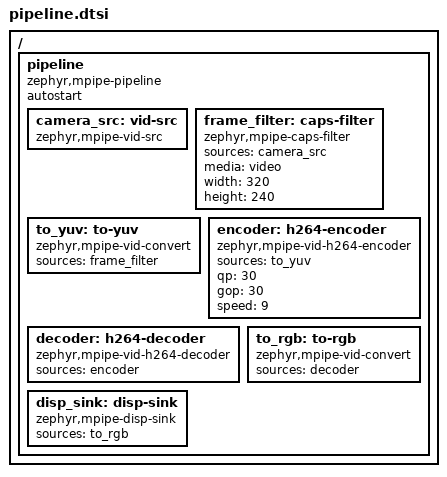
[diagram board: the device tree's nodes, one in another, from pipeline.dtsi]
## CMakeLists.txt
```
# Copyright 2026 NXP
# SPDX-License-Identifier: Apache-2.0

cmake_minimum_required(VERSION 3.20.0)
find_package(Zephyr REQUIRED HINTS $ENV{ZEPHYR_BASE})
project(mpipe_h264_enc_dec)

target_sources(app PRIVATE src/main.c)

if(CONFIG_CODEC_CODE_RELOCATE)
  # The code every frame goes through: the two codec libraries and the pixel
  # format conversions.
  zephyr_code_relocate(LIBRARY modules__minih264
    LOCATION "${CONFIG_CODEC_CODE_RAM_NAME}_TEXT" NOKEEP)
  zephyr_code_relocate(LIBRARY modules__h264swdec
    LOCATION "${CONFIG_CODEC_CODE_RAM_NAME}_TEXT" NOKEEP)
  zephyr_code_relocate(FILES ${ZEPHYR_BASE}/subsys/mpipe/vid/mpipe_vid_convert_table.c
    LOCATION "${CONFIG_CODEC_CODE_RAM_NAME}_TEXT" NOKEEP)
endif()

if(CONFIG_CODEC_DATA_RELOCATE)
  # The memory the codecs work in: the state and working area of the encoder,
  # the heap of the decoder.
  zephyr_code_relocate(FILES ${ZEPHYR_BASE}/subsys/mpipe/vid/mpipe_vid_h264_encoder.c
    LOCATION "${CONFIG_CODEC_ENCODER_RAM_NAME}_BSS" NOKEEP)
  zephyr_code_relocate(FILES ${ZEPHYR_BASE}/modules/h264swdec/zephyr_h264swdec.c
    LOCATION "${CONFIG_CODEC_DECODER_RAM_NAME}_NOINIT" NOKEEP)
endif()
```

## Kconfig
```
# Copyright 2026 NXP
# SPDX-License-Identifier: Apache-2.0

mainmenu "H.264 encode and decode pipeline sample"

menu "H.264 encode and decode pipeline configuration"

config CODEC_CODE_RELOCATE
	bool "Relocate the codec code into RAM"
	select CODE_DATA_RELOCATION
	help
	  Run the encoder, the decoder and the pixel format conversions from
	  RAM instead of the flash. On a microcontroller that executes in
	  place from a serial flash this is where most of their time goes.

if CODEC_CODE_RELOCATE

config CODEC_CODE_RAM_NAME
	string "Codec code RAM location"
	default "RAM"
	help
	  Memory region the codec code is relocated to.

endif # CODEC_CODE_RELOCATE

config CODEC_DATA_RELOCATE
	bool "Relocate the codec memory"
	select CODE_DATA_RELOCATION
	help
	  Place the state and working area of the encoder and the heap of the
	  decoder in named memory regions, on a board whose default RAM is
	  slower than another one it has.

if CODEC_DATA_RELOCATE

config CODEC_ENCODER_RAM_NAME
	string "Encoder memory location"
	default "RAM"
	help
	  Memory region holding the state and working area of the encoder.

config CODEC_DECODER_RAM_NAME
	string "Decoder memory location"
	default "RAM"
	help
	  Memory region holding the heap of the decoder.

endif # CODEC_DATA_RELOCATE

endmenu

source "Kconfig.zephyr"
```

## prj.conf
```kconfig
CONFIG_LOG=y

# The framework, its elements and the player are enabled by the pipeline node
CONFIG_MPIPE_STRUCTURE_MAX_FIELDS=4
# Buffer headers in flight: the camera frame, the two converted frames, the
# frame on screen, slack
CONFIG_MPIPE_NET_BUF_POOL_COUNT=6

# Video buffers of every pool in the image: the camera's own queue of 320x240
# BGRX32 frames, the frames of the two converters, slack
CONFIG_VIDEO_BUFFER_POOL_NUM_MAX=10
CONFIG_VIDEO_BUFFER_POOL_HEAP_SIZE=2097152

# Picture buffers of the decoder for a 320x240 stream
CONFIG_H264SWDEC_HEAP_SIZE=393216
CONFIG_H264SWDEC_MAX_FRAME_WIDTH=320
CONFIG_H264SWDEC_MAX_FRAME_HEIGHT=240
CONFIG_H264SWDEC_MAX_FRAME_SIZE=76800

# The bus carries end-of-stream and errors, never data: it needs neither
# zbus priority boost nor zbus logging of its own.
CONFIG_ZBUS_PRIORITY_BOOST=n
CONFIG_ZBUS_LOG_LEVEL_ERR=y
```

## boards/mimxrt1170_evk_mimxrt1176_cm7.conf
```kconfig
# The decoded frames are scanned out from a display plane: no driver framebuffer
CONFIG_MCUX_LCDIFV2_FB_NUM=0

# The encoder and the decoder run in the streaming thread
CONFIG_MPIPE_THREAD_STACK_SIZE=32768

# The flash is a serial one: the codecs run from the instruction TCM
CONFIG_CODEC_CODE_RELOCATE=y
CONFIG_CODEC_CODE_RAM_NAME="ITCM"

# The default RAM is the SDRAM: the codecs work in the on-chip RAM
CONFIG_CODEC_DATA_RELOCATE=y
CONFIG_CODEC_ENCODER_RAM_NAME="OCRAM1"
CONFIG_CODEC_DECODER_RAM_NAME="OCRAM2"

# Code that runs from RAM gains from being optimized for speed
CONFIG_SPEED_OPTIMIZATIONS=y
```

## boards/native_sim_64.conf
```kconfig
# Bind the native PTY UART to stdin/stdout so the shell reads keystrokes typed
# on the launching terminal.
CONFIG_UART_NATIVE_PTY_0_ON_STDINOUT=y

# Log directly to stdout via the native backend, which is active from boot,
# and not a second time through the shell.
CONFIG_LOG_BACKEND_NATIVE_POSIX=y
CONFIG_SHELL_LOG_BACKEND=n

# Threads on native_sim run on host stacks, so this size is never used and
# only reserves memory.
CONFIG_MPIPE_PLAYER_WORKER_STACK_SIZE=64
```

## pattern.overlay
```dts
/*
 * Copyright 2026 NXP
 *
 * SPDX-License-Identifier: Apache-2.0
 */

/*
 * A pattern that moves, drawn over the camera frames before they are encoded:
 * the codecs then have the same work on every board and in every light.
 */
&{/pipeline} {
	pattern: pattern {
		compatible = "zephyr,mpipe-vid-overlay";
		sources = <&frame_filter>;
		mode = "in-place";
		draw-callback = "sample_draw_pattern";
	};
};

&to_yuv {
	sources = <&pattern>;
};
```

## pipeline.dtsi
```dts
/*
 * Copyright 2026 NXP
 *
 * SPDX-License-Identifier: Apache-2.0
 */

/*
 * Camera frames encoded to H.264, decoded again and displayed: what the
 * display shows is what a receiver of the stream would see.
 *
 *   vid_src -> caps_filter -> vid_convert -> vid_h264_encoder
 *           -> vid_h264_decoder -> vid_convert -> disp_sink
 */
/ {
	pipeline {
		compatible = "zephyr,mpipe-pipeline";
		autostart;

		camera_src: vid-src {
			compatible = "zephyr,mpipe-vid-src";
		};

		/* The frame size the memory of the encoder is reserved for */
		frame_filter: caps-filter {
			compatible = "zephyr,mpipe-caps-filter";
			sources = <&camera_src>;
			media = "video";
			width = <320>;
			height = <240>;
		};

		to_yuv: to-yuv {
			compatible = "zephyr,mpipe-vid-convert";
			sources = <&frame_filter>;
		};

		/* Speed 9 is the fastest setting that keeps the deblocking filter */
		encoder: h264-encoder {
			compatible = "zephyr,mpipe-vid-h264-encoder";
			sources = <&to_yuv>;
			qp = <30>;
			gop = <30>;
			speed = <9>;
		};

		decoder: h264-decoder {
			compatible = "zephyr,mpipe-vid-h264-decoder";
			sources = <&encoder>;
		};

		to_rgb: to-rgb {
			compatible = "zephyr,mpipe-vid-convert";
			sources = <&decoder>;
		};

		disp_sink: disp-sink {
			compatible = "zephyr,mpipe-disp-sink";
			sources = <&to_rgb>;
		};
	};
};
```

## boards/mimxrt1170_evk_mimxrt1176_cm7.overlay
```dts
/*
 * Copyright 2026 NXP
 *
 * SPDX-License-Identifier: Apache-2.0
 */

#include "../pipeline.dtsi"

/* The decoded frames are scanned out from a display plane, without a copy */
&disp_sink {
	plane = <0>;
};
```

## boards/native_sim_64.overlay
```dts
/*
 * Copyright 2026 NXP
 *
 * SPDX-License-Identifier: Apache-2.0
 */

#include "../pipeline.dtsi"

/* The emulated camera never ends: stop after a second of frames */
&camera_src {
	num-buffers = <30>;
};
```

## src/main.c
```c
/*
 * Copyright 2026 NXP
 *
 * SPDX-License-Identifier: Apache-2.0
 */

/*
 * The pipeline is described in pipeline.dtsi and built and played at boot.
 * The application only brings the test pattern.
 */

#include <zephyr/drivers/video.h>
#include <zephyr/net_buf.h>
#include <zephyr/sys/util.h>

#define PATTERN_BLOCK_SIZE 96U

void sample_draw_pattern(uint8_t *frame, uint16_t width, uint16_t height, uint32_t pixfmt,
			 const struct net_buf *in, void *user_data);

/*
 * The draw callback pattern.overlay names: a gradient, and a textured block
 * that moves and changes from frame to frame.
 */
void sample_draw_pattern(uint8_t *frame, uint16_t width, uint16_t height, uint32_t pixfmt,
			 const struct net_buf *in, void *user_data)
{
	static uint32_t n;
	uint32_t *pixel = (uint32_t *)frame;
	uint32_t block_x = (4U * n) % (width - PATTERN_BLOCK_SIZE);
	uint32_t block_y = (2U * n) % (height - PATTERN_BLOCK_SIZE);

	ARG_UNUSED(in);
	ARG_UNUSED(user_data);

	if (pixfmt != VIDEO_PIX_FMT_BGRX32) {
		return;
	}

	for (uint32_t y = 0U; y < height; y++) {
		for (uint32_t x = 0U; x < width; x++) {
			uint32_t grey = (x + (2U * y)) / 2U;

			if ((x - block_x) < PATTERN_BLOCK_SIZE &&
			    (y - block_y) < PATTERN_BLOCK_SIZE) {
				grey = ((4U * (x - block_x)) ^ (4U * (y - block_y))) + (4U * n);
			}

			*pixel++ = (grey & 0xFFU) * 0x010101U;
		}
	}

	n++;
}
```
